# D1H.pdf register map
Vendor: Allwinner; Series: D1H.pdf; File version: 0.1
CPU: XuanTie C906 RISC-V CPU 0, little endian, MPU, FPU, double-precision FPU, 0 interrupt priority bits
Registers are 32-bit, read-write, reset 0x0 unless marked. A register's access mark holds for its fields unless they carry their own. Offsets are from the block's base; [hi:lo] are bit positions; 'fields as' and 'values as' point back to an identical list; <NAME> marks a mode.

## TPADC
Base 0x02009C00
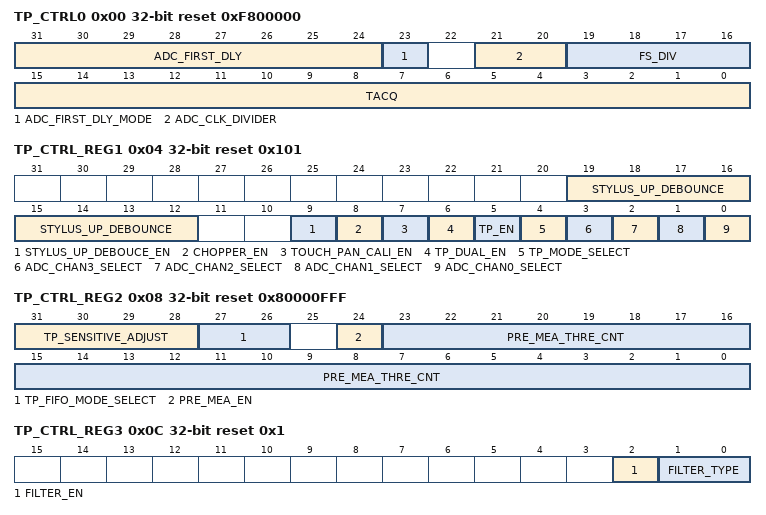
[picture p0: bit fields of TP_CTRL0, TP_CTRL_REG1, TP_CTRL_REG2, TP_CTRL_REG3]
0x00 TP_CTRL0 reset 0xF800000
  [31:24] ADC_FIRST_DLY — ADC First Convert Delay Time (T_FCDT) Setting Based on ADC first convert delay mode select (Bit 23) T_FCDT = *
  [23] ADC_FIRST_DLY_MODE — ADC First Convert Delay Mode Select 0: CLK_IN/16 1: CLK_IN/16*256
    0=CLK_IN_slash_16 (CLK_IN/16); 1=CLK_IN_slash_16_times_256 (CLK_IN/16*256)
  [21:20] ADC_CLK_DIVIDER — ADC Clock Divider (CLK_IN) 00: CLK/2 01: CLK/3 10: CLK/6 11: CLK/1
    0=CLK_slash_2 (CLK/2); 1=CLK_slash_3 (CLK/3); 2=CLK_slash_6 (CLK/6); 3=CLK_slash_1 (CLK/1)
  [19:16] FS_DIV — ADC Sample Frequency Divider 0000: CLK_IN/2 0001: CLK_IN/2 0010: CLK_IN/2 …. 1111: CLK_IN/2
  [15:0] TACQ — Touch panel ADC acquire time CLK_IN/(16*(N+1))
0x04 TP_CTRL_REG1 reset 0x101 — TP Control Register 1
  [19:12] STYLUS_UP_DEBOUNCE — Stylus Up De-bounce Time Setting 0x00: 0 …. 0xFF: 2N*(CLK_IN/16*256)
    0=_0; 255=_2N_times__openingparen_CLK_IN_slash_16_times_256_closingparen_ (2N*(CLK_IN/16*256))
  [9] STYLUS_UP_DEBOUCE_EN — Stylus Up Debounce Function Select 0: Disable 1: Enable
    0=Disable; 1=Enable
  [8] CHOPPER_EN — T-sensor Chopping Enable 0: Disable 1: Enable This field is not used when there is no T-sensor in TPADC
    0=Disable; 1=Enable This field is not used when there is no T-sensor in TPADC
  [7] TOUCH_PAN_CALI_EN — Touch Panel Calibration 1: Start calibration, it is cleared to 0 after calibration
    1=Start calibration, it is cleared to 0 after calibration
  [6] TP_DUAL_EN — Touch Panel Double Point Enable 0: Disable 1: Enable
    0=Disable; 1=Enable
  [5] TP_EN — TP Function Enable 0: Disable 1: Enable
    0=Disable; 1=Enable
  [4] TP_MODE_SELECT — Touch Panel Mode and Auxiliary ADC Mode Select 0: TP 1: Auxiliary ADC
    0=TP; 1=Auxiliary ADC
  [3] ADC_CHAN3_SELECT — Analog Input Channel 3 Select 0: Disable 1: Enable
    0=Disable; 1=Enable
  [2] ADC_CHAN2_SELECT — Analog Input Channel 2 Select 0: Disable 1: Enable
    0=Disable; 1=Enable
  [1] ADC_CHAN1_SELECT — Analog Input Channel 1 Select 0: Disable 1: Enable
    0=Disable; 1=Enable
  [0] ADC_CHAN0_SELECT — Analog Input Channel 0 Select 0: Disable 1: Enable CHAN0–3 can be selected at the same time. If N channel is selected, each channel has 1/N full speed of the ADC. If only one channel is selected, it has the full conversion rate. CHAN0–3 correspond to TP_YN, TP_YP, TP_XN, TP_XP.
    0=Disable; 1=Enable CHAN0–3 can be selected at the same time. If N channel is selected, each channel has 1/N full speed of the ADC. If only one channel is selected, it has the full conversion rate. CHAN0–3 correspond to TP_YN, TP_YP, TP_XN, TP_XP.
0x08 TP_CTRL_REG2 reset 0x80000FFF — TP Control Register 2
  [31:28] TP_SENSITIVE_ADJUST — Internal Pull-up Resistor Control 0000: least sensitive …… 1111: most sensitive This field is used to adjust sensitivity of pen down detection.
    0=least sensitive ……; 15=most sensitive This field is used to adjust sensitivity of pen down detection
  [27:26] TP_FIFO_MODE_SELECT — TP FIFO Access Data Mode Select 00: FIFO store X1,Y1 data for single touch no pressure mode 01: FIFO store X1,Y1, X, Y data for dual touch no pressure mode 10: FIFO store X1,Y1, X2,Y2 data for dual touch no pressure mode 11: FIFO store X1,Y1, X2,Y2,Z1,Z2 data for dual touch and pressure mode The ADC output data in single touch mode can store in FIFO with TP_FIFO_MODE_SELECT configured as 01,10,11. But the data X, Y is theoretically equal to X1,Y1, and X2,Y2 is equal to 0. When PRE_MEA_EN is set and TP_FIFO_MODE_SELECT is not configured as 2’b11, X and Y data will not be stored unless x1*(z2- z1)/z1 < PRE_MEA_THRE_CNT. Z data will always be zero when TP_FIFO_MODE_SELECT is configured as 2’b11 but PRE_MEA_EN is not set.
    0=FIFO_store_X1_comma_Y1_data (FIFO store X1,Y1 data for single touch no pressure mode); 1=FIFO_store_X1_comma_Y1_comma__X (FIFO store X1,Y1, X, Y data for dual touch no pressure mode); 2=FIFO_store_X1_comma_Y1_comma__X2_comma_Y2_data (FIFO store X1,Y1, X2,Y2 data for dual touch no pressure mode); 3=FIFO_store_X1_comma_Y1_comma__X2_comma_Y2_comma_Z1_comma_Z2_data (FIFO store X1,Y1, X2,Y2,Z1,Z2 data for dual touch and pressure mode The ADC output data in single touch mode can store in FIFO with TP_FIFO_MODE_SELECT configured as 01,10,11. But the data X, Y is theoretically equal to X1,Y1, and X2,Y2 is equal to 0. When PRE_MEA_EN is set and TP_FIFO_MODE_SELECT is not configured as 2’b11, X and Y data will not be stored unless x1*(z2- z1)/z1 < PRE_MEA_THRE_CNT. Z data will always be zero when TP_FIFO_MODE_SELECT is configured as 2’b11 but PRE_MEA_EN is not set.)
  [24] PRE_MEA_EN — TP Pressure Measurement Enable Control 0: Disable 1: Enable
    0=Disable; 1=Enable
  [23:0] PRE_MEA_THRE_CNT — TP Pressure Measurement Threshold Control 0x000000:least sensitive 0xFFFFFF: most sensitive This field is used to adjust sensitivity of touch.
    0xFFFFFF=most sensitive This field is used to adjust sensitivity of touch
0x0C TP_CTRL_REG3 reset 0x1 — TP Control Register 3
  [2] FILTER_EN — Filter Enable 0: Disable 1: Enable
    0=Disable; 1=Enable
  [1:0] FILTER_TYPE — Filter Type 00: 4/2 01: 5/3 10: 8/4 11: 16/8
    0=_4_slash_2 (4/2); 1=_5_slash_3 (5/3); 2=_8_slash_4 (8/4); 3=_16_slash_8 (16/8)
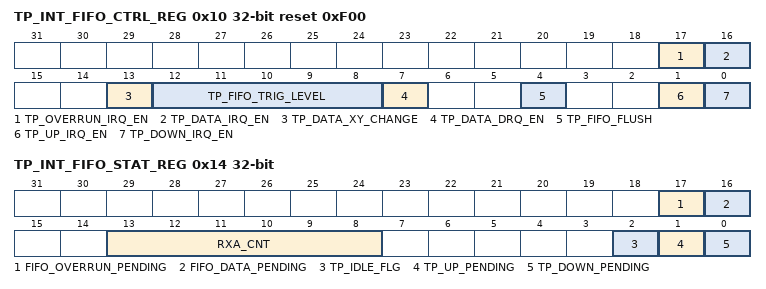
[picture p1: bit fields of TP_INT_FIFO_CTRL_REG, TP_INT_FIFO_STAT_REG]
0x10 TP_INT_FIFO_CTRL_REG reset 0xF00 — TP Interrupt FIFO Control Register
  [17] TP_OVERRUN_IRQ_EN — TP FIFO Overrun IRQ Enable 0: Disable 1: Enable
    0=Disable; 1=Enable
  [16] TP_DATA_IRQ_EN — TP FIFO Data Available IRQ Enable 0: Disable 1: Enable
    0=Disable; 1=Enable
  [13] TP_DATA_XY_CHANGE — TP FIFO X,Y Data Interchange Function Select 0: Disable 1: Enable
    0=Disable; 1=Enable
  [12:8] TP_FIFO_TRIG_LEVEL — TP FIFO Data Available Trigger Level Interrupt and DMA request trigger level for TP or Auxiliary ADC Trigger Level = TXTL + 1
  [7] TP_DATA_DRQ_EN — TP FIFO Data Available DRQ Enable 0: Disable 1: Enable
    0=Disable; 1=Enable
  [4] TP_FIFO_FLUSH — TP FIFO Flush Write ‘1’ to flush TX FIFO, self clear to ‘0’
  [1] TP_UP_IRQ_EN — Touch Panel Last Touch (Stylus Up) IRQ Enable 0: Disable 1: Enable
    0=Disable; 1=Enable
  [0] TP_DOWN_IRQ_EN — Touch Panel First Touch (Stylus Down) IRQ Enable 0: Disable 1: Enable
    0=Disable; 1=Enable
0x14 TP_INT_FIFO_STAT_REG — TP Interrupt FIFO Status Register
  [17] FIFO_OVERRUN_PENDING write-1-clears — TP FIFO Overrun IRQ pending 0: No Pending IRQ 1: FIFO Overrun Pending IRQ Write ‘1’ to clear this interrupt or automatically clear if interrupt condition fails.
    0=No Pending IRQ; 1=FIFO (FIFO Overrun Pending IRQ Write ‘1’ to clear this interrupt or automatically clear if interrupt condition fails.)
  [16] FIFO_DATA_PENDING write-1-clears — TP FIFO Data Available Pending Bit 0: NO Pending IRQ 1: FIFO Available Pending IRQ Write ‘1’ to clear this interrupt or automatically clear if FIFO flushed.
    0=NO Pending IRQ; 1=FIFO (FIFO Available Pending IRQ Write ‘1’ to clear this interrupt or automatically clear if FIFO flushed.)
  [13:8] RXA_CNT ro — TP FIFO Available Sample Word Counter
  [2] TP_IDLE_FLG ro — Touch Panel Idle Flag 0: idle 1: not idle
    0=idle; 1=not_idle
  [1] TP_UP_PENDING write-1-clears — Touch Panel Last Touch (Stylus Up) IRQ Pending bit 0: No IRQ 1: IRQ Writing 1 to the bit clears it and its corresponding interrupt if the interrupt is enabled.
    0=No_IRQ; 1=IRQ (IRQ Writing 1 to the bit clears it and its corresponding interrupt if the interrupt is enabled.)
  [0] TP_DOWN_PENDING write-1-clears — Touch Panel First Touch (Stylus Down) IRQ Pending bit 0: No IRQ 1: IRQ Writing 1 to the bit clears it and its corresponding interrupt if the interrupt is enabled.
    values as TP_UP_PENDING
0x1C TP_CALI_DATA_REG reset 0x800 — TP Calibration Data Register
  [11:0] TP_CDAT — TP Common Data It is used to adjust the tolerance of the internal ADC.
0x24 TP_DATA_REG — TP Data Register
  [11:0] TP_DATA ro — Touch Panel X ,Y data or Auxiliary analogy input data converted by the internal ADC.
